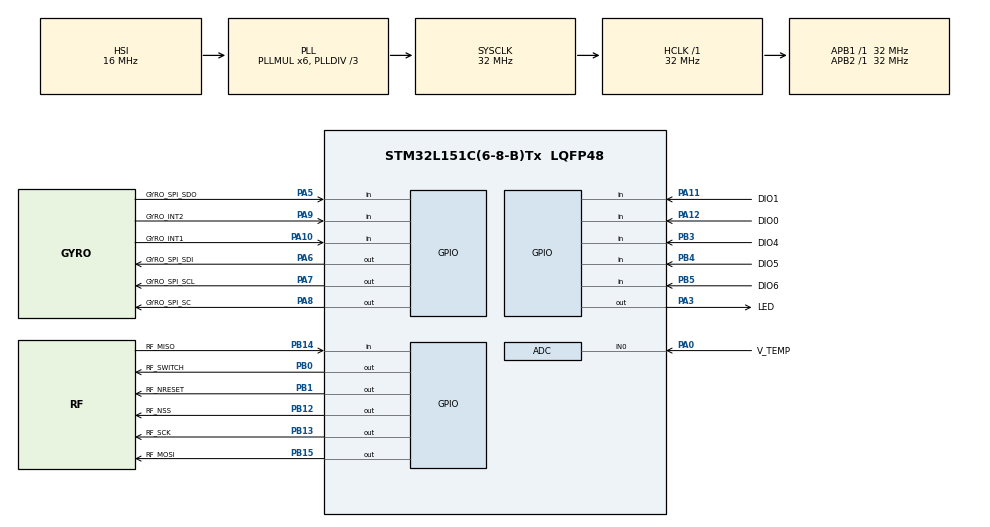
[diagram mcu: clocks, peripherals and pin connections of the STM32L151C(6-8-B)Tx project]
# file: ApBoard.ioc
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ADC.Channel-0\#ChannelRegularConversion=ADC_CHANNEL_0
ADC.ContinuousConvMode=ENABLE
ADC.DMAContinuousRequests=ENABLE
ADC.NbrOfConversionFlag=1
ADC.Rank-0\#ChannelRegularConversion=1
ADC.SamplingTime-0\#ChannelRegularConversion=ADC_SAMPLETIME_384CYCLES
ADC.ScanConvMode=ADC_SCAN_ENABLE
Dma.ADC.0.Direction=DMA_PERIPH_TO_MEMORY
Dma.ADC.0.Instance=DMA1_Channel1
Dma.ADC.0.MemDataAlignment=DMA_MDATAALIGN_HALFWORD
Dma.ADC.0.MemInc=DMA_MINC_ENABLE
Dma.ADC.0.Mode=DMA_CIRCULAR
Dma.ADC.0.PeriphDataAlignment=DMA_PDATAALIGN_HALFWORD
Dma.ADC.0.PeriphInc=DMA_PINC_DISABLE
Dma.ADC.0.Priority=DMA_PRIORITY_LOW
Dma.Request0=ADC
Mcu.Family=STM32L1
Mcu.Name=STM32L151C(6-8-B)Tx
Mcu.Package=LQFP48
NVIC.DMA1_Channel1_IRQn=true\:0\:0\:false\:false\:true
NVIC.PriorityGroup=NVIC_PRIORITYGROUP_4
PA0-WKUP1.GPIO_Label=V_TEMP
PA0-WKUP1.Mode=IN0
PA0-WKUP1.Signal=ADC_IN0
PA10.GPIO_Label=GYRO_INT1
PA10.Signal=GPIO_Input
PA11.GPIO_Label=DIO1
PA11.Signal=GPIO_Input
PA12.GPIO_Label=DIO0
PA12.Signal=GPIO_Input
PA13.Mode=Serial_Wire
PA13.Signal=SYS_JTMS-SWDIO
PA14.Mode=Serial_Wire
PA14.Signal=SYS_JTCK-SWCLK
PA3.GPIO_Label=LED
PA3.Signal=GPIO_Output
PA5.GPIO_Label=GYRO_SPI_SDO
PA5.Signal=GPIO_Input
PA6.GPIO_Label=GYRO_SPI_SDI
PA6.Signal=GPIO_Output
PA7.GPIO_Label=GYRO_SPI_SCL
PA7.Signal=GPIO_Output
PA8.GPIO_Label=GYRO_SPI_SC
PA8.Signal=GPIO_Output
PA9.GPIO_Label=GYRO_INT2
PA9.Signal=GPIO_Input
PB0.GPIO_Label=RF_SWITCH
PB0.Signal=GPIO_Output
PB1.GPIO_Label=RF_NRESET
PB1.Signal=GPIO_Output
PB12.GPIO_Label=RF_NSS
PB12.Signal=GPIO_Output
PB13.GPIO_Label=RF_SCK
PB13.Signal=GPIO_Output
PB14.GPIO_Label=RF_MISO
PB14.Signal=GPIO_Input
PB15.GPIO_Label=RF_MOSI
PB15.Signal=GPIO_Output
PB3.GPIO_Label=DIO4
PB3.Signal=GPIO_Input
PB4.GPIO_Label=DIO5
PB4.Signal=GPIO_Input
PB5.GPIO_Label=DIO6
PB5.Signal=GPIO_Input
PH0-OSC_IN.Mode=HSE-External-Oscillator
PH0-OSC_IN.Signal=RCC_OSC_IN
PH1-OSC_OUT.Mode=HSE-External-Oscillator
PH1-OSC_OUT.Signal=RCC_OSC_OUT
ProjectManager.HeapSize=0x200
ProjectManager.StackSize=0x400
ProjectManager.TargetToolchain=MDK-ARM V5
RCC.AHBFreq_Value=32000000
RCC.APB1Freq_Value=32000000
RCC.APB1TimFreq_Value=32000000
RCC.APB2Freq_Value=32000000
RCC.APB2TimFreq_Value=32000000
RCC.HCLKFreq_Value=32000000
RCC.HSE_VALUE=12000000
RCC.HSI_VALUE=16000000
RCC.LSE_VALUE=32768
RCC.MSI_VALUE=2097000
RCC.PLLDIV=RCC_PLL_DIV3
RCC.PLLMUL=RCC_PLL_MUL6
RCC.SYSCLKFreq_VALUE=32000000
RCC.SYSCLKSource=RCC_SYSCLKSOURCE_PLLCLK
RCC.USBOutput=48000000
RCC.VCOOutputFreq_Value=96000000
board=ApBoard

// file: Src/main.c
/**
  ******************************************************************************
  * File Name          : main.c
  * Description        : Main program body
  ******************************************************************************
  *
  * COPYRIGHT(c) 2017 STMicroelectronics
  *
  * Redistribution and use in source and binary forms, with or without modification,
  * are permitted provided that the following conditions are met:
  *   1. Redistributions of source code must retain the above copyright notice,
  *      this list of conditions and the following disclaimer.
  *   2. Redistributions in binary form must reproduce the above copyright notice,
  *      this list of conditions and the following disclaimer in the documentation
  *      and/or other materials provided with the distribution.
  *   3. Neither the name of STMicroelectronics nor the names of its contributors
  *      may be used to endorse or promote products derived from this software
  *      without specific prior written permission.
  *
  * THIS SOFTWARE IS PROVIDED BY THE COPYRIGHT HOLDERS AND CONTRIBUTORS "AS IS"
  * AND ANY EXPRESS OR IMPLIED WARRANTIES, INCLUDING, BUT NOT LIMITED TO, THE
  * IMPLIED WARRANTIES OF MERCHANTABILITY AND FITNESS FOR A PARTICULAR PURPOSE ARE
  * DISCLAIMED. IN NO EVENT SHALL THE COPYRIGHT HOLDER OR CONTRIBUTORS BE LIABLE
  * FOR ANY DIRECT, INDIRECT, INCIDENTAL, SPECIAL, EXEMPLARY, OR CONSEQUENTIAL
  * DAMAGES (INCLUDING, BUT NOT LIMITED TO, PROCUREMENT OF SUBSTITUTE GOODS OR
  * SERVICES; LOSS OF USE, DATA, OR PROFITS; OR BUSINESS INTERRUPTION) HOWEVER
  * CAUSED AND ON ANY THEORY OF LIABILITY, WHETHER IN CONTRACT, STRICT LIABILITY,
  * OR TORT (INCLUDING NEGLIGENCE OR OTHERWISE) ARISING IN ANY WAY OUT OF THE USE
  * OF THIS SOFTWARE, EVEN IF ADVISED OF THE POSSIBILITY OF SUCH DAMAGE.
  *
  ******************************************************************************
  */
#include "main.h"
#include "stm32l1xx_hal.h"

/* USER CODE BEGIN Includes */
#include "system.h"
/* USER CODE END Includes */

ADC_HandleTypeDef hadc;
DMA_HandleTypeDef hdma_adc;

/* USER CODE BEGIN PV */
/* Private variables ---------------------------------------------------------*/

/* USER CODE END PV */

void SystemClock_Config(void);
void Error_Handler(void);
static void MX_GPIO_Init(void);
static void MX_DMA_Init(void);
static void MX_ADC_Init(void);

/* USER CODE BEGIN PFP */
/* Private function prototypes -----------------------------------------------*/

/* USER CODE END PFP */

int main(void)
{

  /* MCU Configuration----------------------------------------------------------*/

  /* Reset of all peripherals, Initializes the Flash interface and the Systick. */
  HAL_Init();

  /* Configure the system clock */
  SystemClock_Config();

  /* Initialize all configured peripherals */
  MX_GPIO_Init();
  MX_DMA_Init();
  MX_ADC_Init();

  /* USER CODE BEGIN 2 */
  Sys_Task_Init();
  /* USER CODE END 2 */

  /* Infinite loop */
  while (1)
  {

  /* USER CODE BEGIN 3 */
	Sys_Task();
  }
  /* USER CODE END 3 */

}

/** System Clock Configuration
*/
void SystemClock_Config(void)
{

  RCC_OscInitTypeDef RCC_OscInitStruct;
  RCC_ClkInitTypeDef RCC_ClkInitStruct;

    /**Configure the main internal regulator output voltage
    */
  __HAL_PWR_VOLTAGESCALING_CONFIG(PWR_REGULATOR_VOLTAGE_SCALE1);

    /**Initializes the CPU, AHB and APB busses clocks
    */
  RCC_OscInitStruct.OscillatorType = RCC_OSCILLATORTYPE_HSI;
  RCC_OscInitStruct.HSIState = RCC_HSI_ON;
  RCC_OscInitStruct.HSICalibrationValue = 16;
  RCC_OscInitStruct.PLL.PLLState = RCC_PLL_ON;
  RCC_OscInitStruct.PLL.PLLSource = RCC_PLLSOURCE_HSI;
  RCC_OscInitStruct.PLL.PLLMUL = RCC_PLL_MUL6;
  RCC_OscInitStruct.PLL.PLLDIV = RCC_PLL_DIV3;
  if (HAL_RCC_OscConfig(&RCC_OscInitStruct) != HAL_OK)
  {
    Error_Handler();
  }

    /**Initializes the CPU, AHB and APB busses clocks
    */
  RCC_ClkInitStruct.ClockType = RCC_CLOCKTYPE_HCLK|RCC_CLOCKTYPE_SYSCLK
                              |RCC_CLOCKTYPE_PCLK1|RCC_CLOCKTYPE_PCLK2;
  RCC_ClkInitStruct.SYSCLKSource = RCC_SYSCLKSOURCE_PLLCLK;
  RCC_ClkInitStruct.AHBCLKDivider = RCC_SYSCLK_DIV1;
  RCC_ClkInitStruct.APB1CLKDivider = RCC_HCLK_DIV1;
  RCC_ClkInitStruct.APB2CLKDivider = RCC_HCLK_DIV1;

  if (HAL_RCC_ClockConfig(&RCC_ClkInitStruct, FLASH_LATENCY_1) != HAL_OK)
  {
    Error_Handler();
  }

    /**Configure the Systick interrupt time
    */
  HAL_SYSTICK_Config(HAL_RCC_GetHCLKFreq()/1000);

    /**Configure the Systick
    */
  HAL_SYSTICK_CLKSourceConfig(SYSTICK_CLKSOURCE_HCLK);

  /* SysTick_IRQn interrupt configuration */
  HAL_NVIC_SetPriority(SysTick_IRQn, 0, 0);
}

/* ADC init function */
static void MX_ADC_Init(void)
{

  ADC_ChannelConfTypeDef sConfig;

    /**Configure the global features of the ADC (Clock, Resolution, Data Alignment and number of conversion)
    */
  hadc.Instance = ADC1;
  hadc.Init.ClockPrescaler = ADC_CLOCK_ASYNC_DIV1;
  hadc.Init.Resolution = ADC_RESOLUTION_12B;
  hadc.Init.DataAlign = ADC_DATAALIGN_RIGHT;
  hadc.Init.ScanConvMode = ADC_SCAN_ENABLE;
  hadc.Init.EOCSelection = ADC_EOC_SEQ_CONV;
  hadc.Init.LowPowerAutoWait = ADC_AUTOWAIT_DISABLE;
  hadc.Init.LowPowerAutoPowerOff = ADC_AUTOPOWEROFF_DISABLE;
  hadc.Init.ChannelsBank = ADC_CHANNELS_BANK_A;
  hadc.Init.ContinuousConvMode = ENABLE;
  hadc.Init.NbrOfConversion = 1;
  hadc.Init.DiscontinuousConvMode = DISABLE;
  hadc.Init.ExternalTrigConv = ADC_SOFTWARE_START;
  hadc.Init.ExternalTrigConvEdge = ADC_EXTERNALTRIGCONVEDGE_NONE;
  hadc.Init.DMAContinuousRequests = ENABLE;
  if (HAL_ADC_Init(&hadc) != HAL_OK)
  {
    Error_Handler();
  }

    /**Configure for the selected ADC regular channel its corresponding rank in the sequencer and its sample time.
    */
  sConfig.Channel = ADC_CHANNEL_0;
  sConfig.Rank = 1;
  sConfig.SamplingTime = ADC_SAMPLETIME_384CYCLES;
  if (HAL_ADC_ConfigChannel(&hadc, &sConfig) != HAL_OK)
  {
    Error_Handler();
  }

}

static void MX_DMA_Init(void)
{
  /* DMA controller clock enable */
  __HAL_RCC_DMA1_CLK_ENABLE();

  /* DMA interrupt init */
  /* DMA1_Channel1_IRQn interrupt configuration */
  HAL_NVIC_SetPriority(DMA1_Channel1_IRQn, 0, 0);
  HAL_NVIC_EnableIRQ(DMA1_Channel1_IRQn);

}

/** Configure pins as
        * Analog
        * Input
        * Output
        * EVENT_OUT
        * EXTI
*/
static void MX_GPIO_Init(void)
{

  GPIO_InitTypeDef GPIO_InitStruct;

  /* GPIO Ports Clock Enable */
  __HAL_RCC_GPIOH_CLK_ENABLE();
  __HAL_RCC_GPIOA_CLK_ENABLE();
  __HAL_RCC_GPIOB_CLK_ENABLE();

  /*Configure GPIO pin Output Level */
  HAL_GPIO_WritePin(GPIOA, LED_Pin|GYRO_SPI_SDI_Pin|GYRO_SPI_SCL_Pin|GYRO_SPI_SC_Pin, GPIO_PIN_RESET);

  /*Configure GPIO pin Output Level */
  HAL_GPIO_WritePin(GPIOB, RF_SWITCH_Pin|RF_NRESET_Pin|RF_NSS_Pin|RF_SCK_Pin
                          |RF_MOSI_Pin, GPIO_PIN_RESET);

  /*Configure GPIO pins : LED_Pin GYRO_SPI_SDI_Pin GYRO_SPI_SCL_Pin GYRO_SPI_SC_Pin */
  GPIO_InitStruct.Pin = LED_Pin|GYRO_SPI_SDI_Pin|GYRO_SPI_SCL_Pin|GYRO_SPI_SC_Pin;
  GPIO_InitStruct.Mode = GPIO_MODE_OUTPUT_PP;
  GPIO_InitStruct.Pull = GPIO_NOPULL;
  GPIO_InitStruct.Speed = GPIO_SPEED_FREQ_LOW;
  HAL_GPIO_Init(GPIOA, &GPIO_InitStruct);

  /*Configure GPIO pins : GYRO_SPI_SDO_Pin GYRO_INT2_Pin GYRO_INT1_Pin DIO1_Pin
                           DIO0_Pin */
  GPIO_InitStruct.Pin = GYRO_SPI_SDO_Pin|GYRO_INT2_Pin|GYRO_INT1_Pin|DIO1_Pin
                          |DIO0_Pin;
  GPIO_InitStruct.Mode = GPIO_MODE_INPUT;
  GPIO_InitStruct.Pull = GPIO_NOPULL;
  HAL_GPIO_Init(GPIOA, &GPIO_InitStruct);

  /*Configure GPIO pins : RF_SWITCH_Pin RF_NRESET_Pin RF_NSS_Pin RF_SCK_Pin
                           RF_MOSI_Pin */
  GPIO_InitStruct.Pin = RF_SWITCH_Pin|RF_NRESET_Pin|RF_NSS_Pin|RF_SCK_Pin
                          |RF_MOSI_Pin;
  GPIO_InitStruct.Mode = GPIO_MODE_OUTPUT_PP;
  GPIO_InitStruct.Pull = GPIO_NOPULL;
  GPIO_InitStruct.Speed = GPIO_SPEED_FREQ_LOW;
  HAL_GPIO_Init(GPIOB, &GPIO_InitStruct);

  /*Configure GPIO pins : RF_MISO_Pin DIO4_Pin DIO5_Pin DIO6_Pin */
  GPIO_InitStruct.Pin = RF_MISO_Pin|DIO4_Pin|DIO5_Pin|DIO6_Pin;
  GPIO_InitStruct.Mode = GPIO_MODE_INPUT;
  GPIO_InitStruct.Pull = GPIO_NOPULL;
  HAL_GPIO_Init(GPIOB, &GPIO_InitStruct);

}

/* USER CODE BEGIN 4 */
#if 0
/************************************************************************************************
*
*@Brief	Keil에서 Printf문 출력(Uart1에서 출력)
*
*************************************************************************************************/
#ifdef __GNUC__
  /* With GCC/RAISONANCE, small printf (option LD Linker->Libraries->Small printf
     set to 'Yes') calls __io_putchar() */
  #define PUTCHAR_PROTOTYPE int __io_putchar(int ch)
#else
  #define PUTCHAR_PROTOTYPE int fputc(int ch, FILE *f)
#endif /* __GNUC__ */

PUTCHAR_PROTOTYPE
{
  HAL_UART_Transmit(&huart1,(uint8_t *)&ch,1,1);
  return ch;
}
#endif
/* USER CODE END 4 */

void Error_Handler(void)
{
  while(1)
  {
  }
}

/************************ (C) COPYRIGHT STMicroelectronics *****END OF FILE****/
